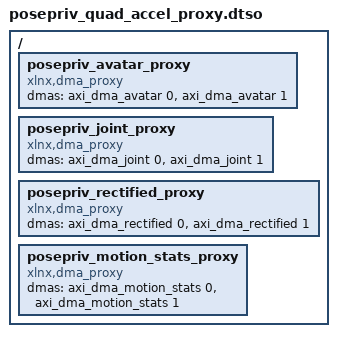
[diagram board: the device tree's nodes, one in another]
/dts-v1/;
/plugin/;

/*
 * 由 config/kv260_dual_accel_hardware.json 生成。
 * DMA 控制器节点和 GIC 中断号必须由与 XSA 匹配的 AMD 设备树生成器提供。
 */
/ {
    fragment@0 {
        target-path = "/";
        __overlay__ {
            posepriv_avatar_proxy {
                compatible = "xlnx,dma_proxy";
                dmas = <&axi_dma_avatar 0>, <&axi_dma_avatar 1>;
                dma-names = "posepriv_avatar_tx", "posepriv_avatar_rx";
                status = "okay";
            };

            posepriv_joint_proxy {
                compatible = "xlnx,dma_proxy";
                dmas = <&axi_dma_joint 0>, <&axi_dma_joint 1>;
                dma-names = "posepriv_joint_tx", "posepriv_joint_rx";
                status = "okay";
            };

            posepriv_rectified_proxy {
                compatible = "xlnx,dma_proxy";
                dmas = <&axi_dma_rectified 0>, <&axi_dma_rectified 1>;
                dma-names = "posepriv_rectified_tx", "posepriv_rectified_rx";
                status = "okay";
            };

            posepriv_motion_stats_proxy {
                compatible = "xlnx,dma_proxy";
                dmas = <&axi_dma_motion_stats 0>, <&axi_dma_motion_stats 1>;
                dma-names = "posepriv_motion_stats_tx", "posepriv_motion_stats_rx";
                status = "okay";
            };
        };
    };
};

/* 硬件核对：avatar=0xA0000000, joint=0xA0010000 */
/* hardware_contract=avatar=0xA0000000, joint=0xA0010000, rectified=0xA0020000, motion_stats=0xA0030000 */
/* source_hwh=posepriv_quad_accel.hwh */
